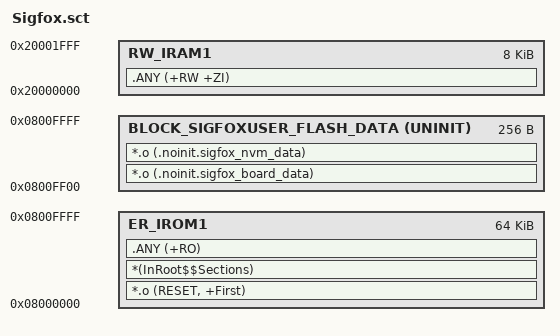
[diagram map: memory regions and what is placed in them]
#! armcc -E
; *************************************************************
; *** Scatter-Loading Description File generated by uVision ***
; *************************************************************

/* Two pages reserved for Sigfox non volatile memory */
#define FLASH_NVM_DATASIZE (2*128)

LR_IROM1 0x08000000 0x00010000  {    ; load region size_region
  ER_IROM1 0x08000000 0x00010000  {  ; load address = execution address
   *.o (RESET, +First)
   *(InRoot$$Sections)
   .ANY (+RO)
  }
  RW_IRAM1 0x20000000 0x00002000  {  ; RW data
   .ANY (+RW +ZI)
  }
  BLOCK_SIGFOXUSER_FLASH_DATA (0x0800FF00) UNINIT FLASH_NVM_DATASIZE  {
  	*.o (.noinit.sigfox_board_data)
  	*.o (.noinit.sigfox_nvm_data)
  }   
}
